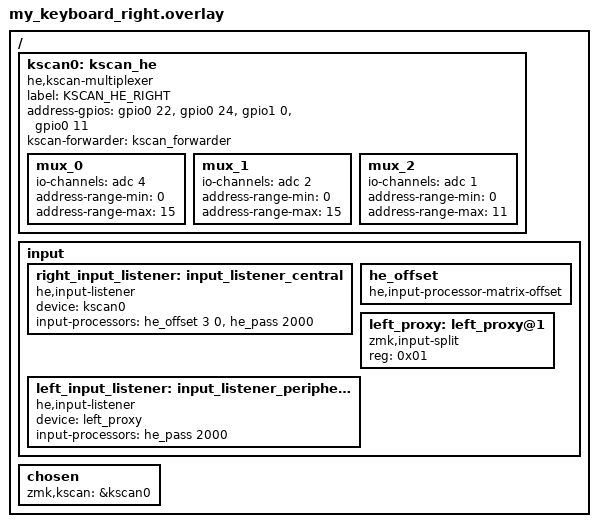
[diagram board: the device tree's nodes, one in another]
#include "../my_keyboard/my_keyboard.dtsi"

/ {
    kscan0: kscan_he {
        compatible = "he,kscan-multiplexer";
        label = "KSCAN_HE_RIGHT";

        address-gpios = <&gpio0 22 GPIO_ACTIVE_HIGH>,  /* D4 */
                        <&gpio0 24 GPIO_ACTIVE_HIGH>,  /* D5 */
                        <&gpio1 0 GPIO_ACTIVE_HIGH>,   /* D6 */
                        <&gpio0 11 GPIO_ACTIVE_HIGH>;  /* D7 */

        kscan-forwarder = <&kscan_forwarder>;
        
        /* 3 Mux Outputs */
        mux_0 {
            io-channels = <&adc 4>; /* A3 */
            address-range-min = <0>;
            address-range-max = <15>;
        };

        mux_1 {
            io-channels = <&adc 2>; /* A2 */
            address-range-min = <0>;
            address-range-max = <15>;
        };

        mux_2 {
            io-channels = <&adc 1>; /* A1 */
            address-range-min = <0>;
            address-range-max = <11>;
        };
    };

    input {
        #address-cells = <1>;
        #size-cells = <0>;

        /* Process local keys (Right half) */
        right_input_listener: input_listener_central {
            compatible = "he,input-listener";
            device = <&kscan0>;
            input-processors = <&he_offset 3 0>, <&he_pass 2000>;
        };

        he_offset: he_offset {
            compatible = "he,input-processor-matrix-offset";
            #input-processor-cells = <2>;
        };

        /* Proxy for left half keys received over BLE */
        left_proxy: left_proxy@1 {
            compatible = "zmk,input-split";
            reg = <0x01>;
        };

        /* Process peripheral keys (Left half) */
        left_input_listener: input_listener_peripheral {
            compatible = "he,input-listener";
            device = <&left_proxy>;
            input-processors = <&he_pass 2000>;
        };
    };

    chosen {
        zmk,kscan = &kscan0;
    };
};
